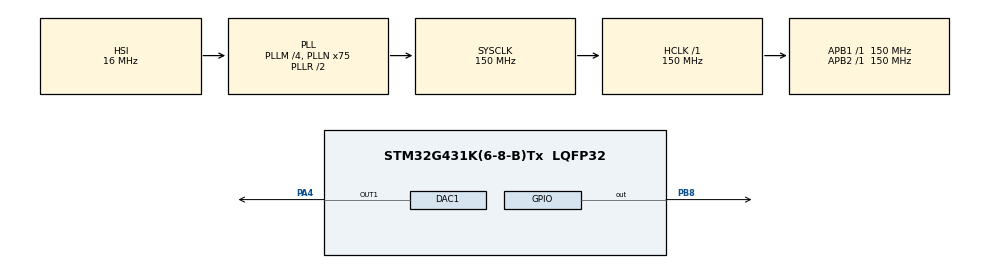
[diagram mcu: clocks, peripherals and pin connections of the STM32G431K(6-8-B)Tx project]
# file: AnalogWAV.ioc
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DAC1.DAC_HighFrequency_OUT1-DAC_OUT1=DAC_HIGH_FREQUENCY_INTERFACE_MODE_AUTOMATIC
DAC1.DAC_Trigger_OUT1-DAC_OUT1=DAC_TRIGGER_NONE
Dma.Request0=TIM8_CH1
Dma.TIM8_CH1.0.Direction=DMA_MEMORY_TO_PERIPH
Dma.TIM8_CH1.0.EventEnable=DISABLE
Dma.TIM8_CH1.0.Instance=DMA1_Channel1
Dma.TIM8_CH1.0.MemDataAlignment=DMA_MDATAALIGN_HALFWORD
Dma.TIM8_CH1.0.MemInc=DMA_MINC_ENABLE
Dma.TIM8_CH1.0.Mode=DMA_CIRCULAR
Dma.TIM8_CH1.0.PeriphDataAlignment=DMA_PDATAALIGN_WORD
Dma.TIM8_CH1.0.PeriphInc=DMA_PINC_DISABLE
Dma.TIM8_CH1.0.Polarity=HAL_DMAMUX_REQ_GEN_RISING
Dma.TIM8_CH1.0.Priority=DMA_PRIORITY_HIGH
Dma.TIM8_CH1.0.RequestNumber=1
Dma.TIM8_CH1.0.SignalID=NONE
Dma.TIM8_CH1.0.SyncEnable=DISABLE
Dma.TIM8_CH1.0.SyncPolarity=HAL_DMAMUX_SYNC_NO_EVENT
Dma.TIM8_CH1.0.SyncRequestNumber=1
Dma.TIM8_CH1.0.SyncSignalID=NONE
Mcu.Family=STM32G4
Mcu.Name=STM32G431K(6-8-B)Tx
Mcu.Package=LQFP32
NUCLEO-G431KB.LD2=true
NUCLEO-G431KB.VCP=true
NVIC.DMA1_Channel1_IRQn=true\:0\:0\:false\:false\:true\:false\:true\:true
NVIC.PriorityGroup=NVIC_PRIORITYGROUP_4
NVIC.TIM8_UP_IRQn=true\:0\:0\:false\:false\:false\:true\:true\:true
PA13.GPIO_Label=T_SWDIO
PA13.Signal=SYS_JTMS-SWDIO
PA14.GPIO_Label=T_SWCLK
PA14.Signal=SYS_JTCK-SWCLK
PA2.Signal=USART2_TX
PA3.Signal=USART2_RX
PA4.Signal=COMP_DAC11_group
PB3.GPIO_Label=T_SWO
PB3.Signal=SYS_JTDO-SWO
PB8-BOOT0.Signal=GPIO_Output
ProjectManager.HeapSize=0x200
ProjectManager.StackSize=0x400
ProjectManager.TargetToolchain=STM32CubeIDE
RCC.ADC12Freq_Value=150000000
RCC.AHBFreq_Value=150000000
RCC.APB1Freq_Value=150000000
RCC.APB1TimFreq_Value=150000000
RCC.APB2Freq_Value=150000000
RCC.APB2TimFreq_Value=150000000
RCC.CortexFreq_Value=150000000
RCC.EXTERNAL_CLOCK_VALUE=12288000
RCC.HCLKFreq_Value=150000000
RCC.HSE_VALUE=8000000
RCC.HSI48_VALUE=48000000
RCC.HSI_VALUE=16000000
RCC.LSE_VALUE=32768
RCC.PLLM=RCC_PLLM_DIV4
RCC.PLLN=75
RCC.SYSCLKFreq_VALUE=150000000
RCC.SYSCLKSource=RCC_SYSCLKSOURCE_PLLCLK
RCC.USBFreq_Value=150000000
RCC.VCOOutputFreq_Value=300000000
SH.COMP_DAC11_group.0=DAC1_OUT1,DAC_OUT1
TIM2.PeriodNoDither=10000000-1
TIM2.Prescaler=14
TIM2.TIM_MasterOutputTrigger=TIM_TRGO_UPDATE
TIM8.Channel-Output\ Compare1\ No\ Output=TIM_CHANNEL_1
TIM8.PeriodNoDither=999
TIM8.Prescaler=14
TIM8.PulseNoDither_1=999
TIM8.RepetitionCounter=4096
TIM8.TIM_MasterOutputTrigger=TIM_TRGO_OC1
VP_NUCLEO-G431KB_VS_BSP_COMMON.Mode=COMMON
VP_SYS_VS_DBSignals.Mode=DisableDeadBatterySignals
VP_TIM2_VS_ClockSourceINT.Mode=Internal
VP_TIM8_VS_ClockSourceINT.Mode=Internal
VP_TIM8_VS_ClockSourceITR.Mode=TriggerSource_ITR1
VP_TIM8_VS_ControllerModeTrigger.Mode=Trigger Mode
VP_TIM8_VS_OPM.Mode=OPM_bit
VP_TIM8_VS_no_output1.Mode=Output Compare1 No Output
board=NUCLEO-G431KB

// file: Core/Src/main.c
/* USER CODE BEGIN Header */
/**
  ******************************************************************************
  * @file           : main.c
  * @brief          : Main program body
  ******************************************************************************
  * @attention
  *
  * Copyright (c) 2025 STMicroelectronics.
  * All rights reserved.
  *
  * This software is licensed under terms that can be found in the LICENSE file
  * in the root directory of this software component.
  * If no LICENSE file comes with this software, it is provided AS-IS.
  *
  ******************************************************************************
  */
/* USER CODE END Header */
#include "main.h"

COM_InitTypeDef BspCOMInit;

DAC_HandleTypeDef hdac1;

TIM_HandleTypeDef htim2;
TIM_HandleTypeDef htim8;
DMA_HandleTypeDef hdma_tim8_ch1;

/* USER CODE BEGIN PV */
static uint16_t lfsr = 0x3701; // First seed
static int32_t brownian_state = 2048; // Start in the middle of 12-bit range
uint16_t out_seq[4097] = {0};

uint32_t DAC1_mon = 0;
uint32_t DMA_CNT_mon = 0;
uint32_t TIM8_CNT_mon = 0;
uint32_t TIM2_CNT_mon = 0;
uint16_t Seed_mon = 0;
/* USER CODE END PV */

void SystemClock_Config(void);
static void MX_GPIO_Init(void);
static void MX_DMA_Init(void);
static void MX_DAC1_Init(void);
static void MX_TIM2_Init(void);
static void MX_TIM8_Init(void);

/* USER CODE BEGIN 0 */

void TIM8_UP_IRQHandler(void)
{ // Every time TIM8 Finishes with repetition and counting – stops genertate new sequence to be used the next time.

	GenerateSeq(out_seq);
	HAL_TIM_IRQHandler(&htim8);

}

uint16_t white_noise_sample(){
    // 16-bit Galois LFSR (XOR-Shift)
    lfsr ^= lfsr >> 7;
    lfsr ^= lfsr << 9;
    lfsr ^= lfsr >> 13;

    // Mask to 12 bits (0-4095)
    return lfsr & 0x0FFF;
}

uint16_t generate_new_seed(uint16_t current_seed) {
	current_seed = current_seed ^ 0xB400;
	if (current_seed == 0) {current_seed = 1;}
    return current_seed; // Prime-derived XOR mask
}

//Generates a brownian sequence, gets ready for the next time it will be needed
void GenerateSeq(uint16_t *SeqArray){

	for (int i = 0; i < 4096; i++) { //This generates a whole next sequence to be transmitted
		uint16_t white_noise = white_noise_sample();
		int32_t step = (white_noise & 0x7F) - 64; // Small step (-64 to +63)

		if (white_noise & 1) {step += 1;} // Ensure symmetry

		int32_t correction = (2048 - brownian_state) / 256; // Small force toward center
		step += correction;

		brownian_state += step; // Integrate step

		if (brownian_state < 0) {brownian_state = 0;}
		if (brownian_state > 4095) {brownian_state = 4095;}

		SeqArray[i] = (uint16_t)brownian_state;
	}
	brownian_state = 2048;
	lfsr = generate_new_seed(lfsr); //Create new seed for the next generation
}
/* USER CODE END 0 */

int main(void)
{

  /* MCU Configuration--------------------------------------------------------*/

  /* Reset of all peripherals, Initializes the Flash interface and the Systick. */
  HAL_Init();

  /* Configure the system clock */
  SystemClock_Config();

  /* Initialize all configured peripherals */
  MX_GPIO_Init();
  MX_DMA_Init();
  MX_DAC1_Init();
  MX_TIM2_Init();
  MX_TIM8_Init();

  /* Initialize leds */
  BSP_LED_Init(LED_GREEN);

  /* Initialize COM1 port (115200, 8 bits (7-bit data + 1 stop bit), no parity */
  BspCOMInit.BaudRate   = 115200;
  BspCOMInit.WordLength = COM_WORDLENGTH_8B;
  BspCOMInit.StopBits   = COM_STOPBITS_1;
  BspCOMInit.Parity     = COM_PARITY_NONE;
  BspCOMInit.HwFlowCtl  = COM_HWCONTROL_NONE;
  if (BSP_COM_Init(COM1, &BspCOMInit) != BSP_ERROR_NONE)
  {
    Error_Handler();
  }

  /* Infinite loop */
  /* USER CODE BEGIN WHILE */

  //First generation
  GenerateSeq(out_seq);
  out_seq[4096] = 2048; //Last element should be middle rail

  uint32_t *dac_address = (uint32_t *)&(DAC1->DHR12R1);

  HAL_DMA_Init(&hdma_tim8_ch1);
  HAL_DMA_Start(&hdma_tim8_ch1, out_seq, dac_address, 4097); //One more than 4096 because I want the zero to be the last value

  HAL_DAC_Start(&hdac1, DAC1_CHANNEL_1);

  TIM8->DIER |= TIM_DIER_CC1DE; //Autogen misses some registers...
  TIM8->DIER |= TIM_DIER_UIE;
  HAL_TIM_OC_Start_IT(&htim8, TIM_CHANNEL_1);

  TIM2->DIER |= TIM_DIER_UDE;
  HAL_TIM_Base_Start(&htim2);

  while (1)
  {

	  //For monitoring/debug in STM32 Monitor – No functional value

	  DAC1_mon = DAC1->DHR12R1;
	  Seed_mon = lfsr;
	  DMA_CNT_mon = DMA1_Channel1->CNDTR;
	  TIM8_CNT_mon = TIM8->CNT;
	  TIM2_CNT_mon = TIM2->CNT;

    /* USER CODE END WHILE */

  }
}

void SystemClock_Config(void)
{
  RCC_OscInitTypeDef RCC_OscInitStruct = {0};
  RCC_ClkInitTypeDef RCC_ClkInitStruct = {0};

  /** Configure the main internal regulator output voltage
  */
  HAL_PWREx_ControlVoltageScaling(PWR_REGULATOR_VOLTAGE_SCALE1);

  /** Initializes the RCC Oscillators according to the specified parameters
  * in the RCC_OscInitTypeDef structure.
  */
  RCC_OscInitStruct.OscillatorType = RCC_OSCILLATORTYPE_HSI;
  RCC_OscInitStruct.HSIState = RCC_HSI_ON;
  RCC_OscInitStruct.HSICalibrationValue = RCC_HSICALIBRATION_DEFAULT;
  RCC_OscInitStruct.PLL.PLLState = RCC_PLL_ON;
  RCC_OscInitStruct.PLL.PLLSource = RCC_PLLSOURCE_HSI;
  RCC_OscInitStruct.PLL.PLLM = RCC_PLLM_DIV4;
  RCC_OscInitStruct.PLL.PLLN = 75;
  RCC_OscInitStruct.PLL.PLLP = RCC_PLLP_DIV2;
  RCC_OscInitStruct.PLL.PLLQ = RCC_PLLQ_DIV2;
  RCC_OscInitStruct.PLL.PLLR = RCC_PLLR_DIV2;
  if (HAL_RCC_OscConfig(&RCC_OscInitStruct) != HAL_OK)
  {
    Error_Handler();
  }

  /** Initializes the CPU, AHB and APB buses clocks
  */
  RCC_ClkInitStruct.ClockType = RCC_CLOCKTYPE_HCLK|RCC_CLOCKTYPE_SYSCLK
                              |RCC_CLOCKTYPE_PCLK1|RCC_CLOCKTYPE_PCLK2;
  RCC_ClkInitStruct.SYSCLKSource = RCC_SYSCLKSOURCE_PLLCLK;
  RCC_ClkInitStruct.AHBCLKDivider = RCC_SYSCLK_DIV1;
  RCC_ClkInitStruct.APB1CLKDivider = RCC_HCLK_DIV1;
  RCC_ClkInitStruct.APB2CLKDivider = RCC_HCLK_DIV1;

  if (HAL_RCC_ClockConfig(&RCC_ClkInitStruct, FLASH_LATENCY_4) != HAL_OK)
  {
    Error_Handler();
  }
}

static void MX_DAC1_Init(void)
{

  DAC_ChannelConfTypeDef sConfig = {0};

  /** DAC Initialization
  */
  hdac1.Instance = DAC1;
  if (HAL_DAC_Init(&hdac1) != HAL_OK)
  {
    Error_Handler();
  }

  /** DAC channel OUT1 config
  */
  sConfig.DAC_HighFrequency = DAC_HIGH_FREQUENCY_INTERFACE_MODE_AUTOMATIC;
  sConfig.DAC_DMADoubleDataMode = DISABLE;
  sConfig.DAC_SignedFormat = DISABLE;
  sConfig.DAC_SampleAndHold = DAC_SAMPLEANDHOLD_DISABLE;
  sConfig.DAC_Trigger = DAC_TRIGGER_NONE;
  sConfig.DAC_Trigger2 = DAC_TRIGGER_NONE;
  sConfig.DAC_OutputBuffer = DAC_OUTPUTBUFFER_ENABLE;
  sConfig.DAC_ConnectOnChipPeripheral = DAC_CHIPCONNECT_EXTERNAL;
  sConfig.DAC_UserTrimming = DAC_TRIMMING_FACTORY;
  if (HAL_DAC_ConfigChannel(&hdac1, &sConfig, DAC_CHANNEL_1) != HAL_OK)
  {
    Error_Handler();
  }

}

static void MX_TIM2_Init(void)
{

  TIM_ClockConfigTypeDef sClockSourceConfig = {0};
  TIM_MasterConfigTypeDef sMasterConfig = {0};

  htim2.Instance = TIM2;
  htim2.Init.Prescaler = 14;
  htim2.Init.CounterMode = TIM_COUNTERMODE_UP;
  htim2.Init.Period = 9999999;
  htim2.Init.ClockDivision = TIM_CLOCKDIVISION_DIV1;
  htim2.Init.AutoReloadPreload = TIM_AUTORELOAD_PRELOAD_DISABLE;
  if (HAL_TIM_Base_Init(&htim2) != HAL_OK)
  {
    Error_Handler();
  }
  sClockSourceConfig.ClockSource = TIM_CLOCKSOURCE_INTERNAL;
  if (HAL_TIM_ConfigClockSource(&htim2, &sClockSourceConfig) != HAL_OK)
  {
    Error_Handler();
  }
  sMasterConfig.MasterOutputTrigger = TIM_TRGO_UPDATE;
  sMasterConfig.MasterSlaveMode = TIM_MASTERSLAVEMODE_DISABLE;
  if (HAL_TIMEx_MasterConfigSynchronization(&htim2, &sMasterConfig) != HAL_OK)
  {
    Error_Handler();
  }

}

static void MX_TIM8_Init(void)
{

  TIM_ClockConfigTypeDef sClockSourceConfig = {0};
  TIM_SlaveConfigTypeDef sSlaveConfig = {0};
  TIM_MasterConfigTypeDef sMasterConfig = {0};
  TIM_OC_InitTypeDef sConfigOC = {0};
  TIM_BreakDeadTimeConfigTypeDef sBreakDeadTimeConfig = {0};

  htim8.Instance = TIM8;
  htim8.Init.Prescaler = 14;
  htim8.Init.CounterMode = TIM_COUNTERMODE_UP;
  htim8.Init.Period = 999;
  htim8.Init.ClockDivision = TIM_CLOCKDIVISION_DIV1;
  htim8.Init.RepetitionCounter = 4096;
  htim8.Init.AutoReloadPreload = TIM_AUTORELOAD_PRELOAD_DISABLE;
  if (HAL_TIM_Base_Init(&htim8) != HAL_OK)
  {
    Error_Handler();
  }
  sClockSourceConfig.ClockSource = TIM_CLOCKSOURCE_INTERNAL;
  if (HAL_TIM_ConfigClockSource(&htim8, &sClockSourceConfig) != HAL_OK)
  {
    Error_Handler();
  }
  if (HAL_TIM_OC_Init(&htim8) != HAL_OK)
  {
    Error_Handler();
  }
  if (HAL_TIM_OnePulse_Init(&htim8, TIM_OPMODE_SINGLE) != HAL_OK)
  {
    Error_Handler();
  }
  sSlaveConfig.SlaveMode = TIM_SLAVEMODE_TRIGGER;
  sSlaveConfig.InputTrigger = TIM_TS_ITR1;
  if (HAL_TIM_SlaveConfigSynchro(&htim8, &sSlaveConfig) != HAL_OK)
  {
    Error_Handler();
  }
  sMasterConfig.MasterOutputTrigger = TIM_TRGO_OC1;
  sMasterConfig.MasterOutputTrigger2 = TIM_TRGO2_RESET;
  sMasterConfig.MasterSlaveMode = TIM_MASTERSLAVEMODE_DISABLE;
  if (HAL_TIMEx_MasterConfigSynchronization(&htim8, &sMasterConfig) != HAL_OK)
  {
    Error_Handler();
  }
  sConfigOC.OCMode = TIM_OCMODE_TIMING;
  sConfigOC.Pulse = 999;
  sConfigOC.OCPolarity = TIM_OCPOLARITY_HIGH;
  sConfigOC.OCNPolarity = TIM_OCNPOLARITY_HIGH;
  sConfigOC.OCFastMode = TIM_OCFAST_DISABLE;
  sConfigOC.OCIdleState = TIM_OCIDLESTATE_RESET;
  sConfigOC.OCNIdleState = TIM_OCNIDLESTATE_RESET;
  if (HAL_TIM_OC_ConfigChannel(&htim8, &sConfigOC, TIM_CHANNEL_1) != HAL_OK)
  {
    Error_Handler();
  }
  sBreakDeadTimeConfig.OffStateRunMode = TIM_OSSR_DISABLE;
  sBreakDeadTimeConfig.OffStateIDLEMode = TIM_OSSI_DISABLE;
  sBreakDeadTimeConfig.LockLevel = TIM_LOCKLEVEL_OFF;
  sBreakDeadTimeConfig.DeadTime = 0;
  sBreakDeadTimeConfig.BreakState = TIM_BREAK_DISABLE;
  sBreakDeadTimeConfig.BreakPolarity = TIM_BREAKPOLARITY_HIGH;
  sBreakDeadTimeConfig.BreakFilter = 0;
  sBreakDeadTimeConfig.BreakAFMode = TIM_BREAK_AFMODE_INPUT;
  sBreakDeadTimeConfig.Break2State = TIM_BREAK2_DISABLE;
  sBreakDeadTimeConfig.Break2Polarity = TIM_BREAK2POLARITY_HIGH;
  sBreakDeadTimeConfig.Break2Filter = 0;
  sBreakDeadTimeConfig.Break2AFMode = TIM_BREAK_AFMODE_INPUT;
  sBreakDeadTimeConfig.AutomaticOutput = TIM_AUTOMATICOUTPUT_DISABLE;
  if (HAL_TIMEx_ConfigBreakDeadTime(&htim8, &sBreakDeadTimeConfig) != HAL_OK)
  {
    Error_Handler();
  }

}

static void MX_DMA_Init(void)
{

  /* DMA controller clock enable */
  __HAL_RCC_DMAMUX1_CLK_ENABLE();
  __HAL_RCC_DMA1_CLK_ENABLE();

  /* DMA interrupt init */
  /* DMA1_Channel1_IRQn interrupt configuration */
  HAL_NVIC_SetPriority(DMA1_Channel1_IRQn, 0, 0);
  HAL_NVIC_EnableIRQ(DMA1_Channel1_IRQn);

}

static void MX_GPIO_Init(void)
{

  /* GPIO Ports Clock Enable */
  __HAL_RCC_GPIOA_CLK_ENABLE();
  __HAL_RCC_GPIOB_CLK_ENABLE();

}

/* USER CODE BEGIN Header */
/**
  ******************************************************************************
  * @file           : main.c
  * @brief          : Main program body
  ******************************************************************************
  * @attention
  *
  * Copyright (c) 2025 STMicroelectronics.
  * All rights reserved.
  *
  * This software is licensed under terms that can be found in the LICENSE file
  * in the root directory of this software component.
  * If no LICENSE file comes with this software, it is provided AS-IS.
  *
  ******************************************************************************
  */
/* USER CODE END Header */

void Error_Handler(void)
{
  __disable_irq();
  while (1)
  {
  }
}
